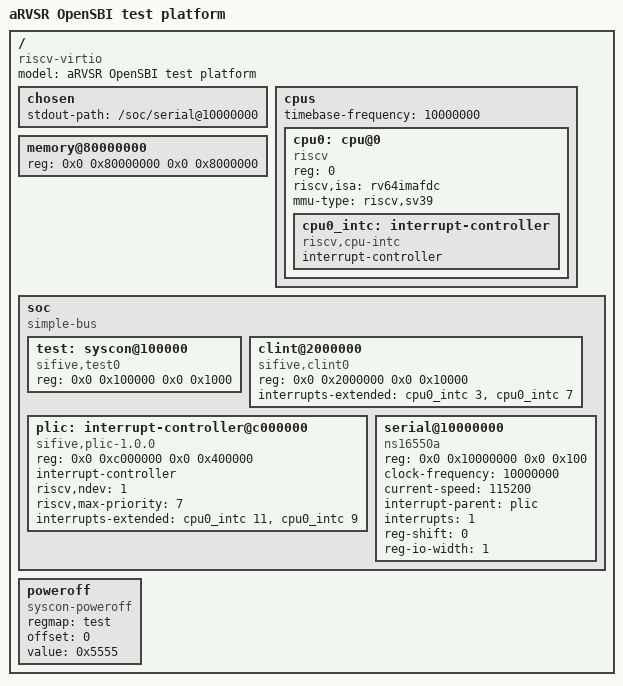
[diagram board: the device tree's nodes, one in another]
/dts-v1/;

/ {
    #address-cells = <2>;
    #size-cells = <2>;
    compatible = "riscv-virtio";
    model = "aRVSR OpenSBI test platform";

    chosen {
        stdout-path = "/soc/serial@10000000";
    };

    cpus {
        #address-cells = <1>;
        #size-cells = <0>;
        timebase-frequency = <10000000>;

        cpu0: cpu@0 {
            device_type = "cpu";
            reg = <0>;
            status = "okay";
            compatible = "riscv";
            riscv,isa = "rv64imafdc";
            mmu-type = "riscv,sv39";

            cpu0_intc: interrupt-controller {
                #interrupt-cells = <1>;
                interrupt-controller;
                compatible = "riscv,cpu-intc";
            };
        };
    };

    memory@80000000 {
        device_type = "memory";
        reg = <0x0 0x80000000 0x0 0x8000000>;
    };

    soc {
        #address-cells = <2>;
        #size-cells = <2>;
        compatible = "simple-bus";
        ranges;

        test: syscon@100000 {
            compatible = "sifive,test0", "syscon";
            reg = <0x0 0x100000 0x0 0x1000>;
        };

        clint@2000000 {
            compatible = "sifive,clint0", "riscv,clint0";
            reg = <0x0 0x2000000 0x0 0x10000>;
            interrupts-extended = <&cpu0_intc 3>, <&cpu0_intc 7>;
        };

        plic: interrupt-controller@c000000 {
            compatible = "sifive,plic-1.0.0", "riscv,plic0";
            reg = <0x0 0xc000000 0x0 0x400000>;
            #interrupt-cells = <1>;
            interrupt-controller;
            riscv,ndev = <1>;
            riscv,max-priority = <7>;
            interrupts-extended = <&cpu0_intc 11>, <&cpu0_intc 9>;
        };

        serial@10000000 {
            compatible = "ns16550a";
            reg = <0x0 0x10000000 0x0 0x100>;
            clock-frequency = <10000000>;
            current-speed = <115200>;
            interrupt-parent = <&plic>;
            interrupts = <1>;
            reg-shift = <0>;
            reg-io-width = <1>;
        };
    };

    poweroff {
        compatible = "syscon-poweroff";
        regmap = <&test>;
        offset = <0>;
        value = <0x5555>;
    };
};
